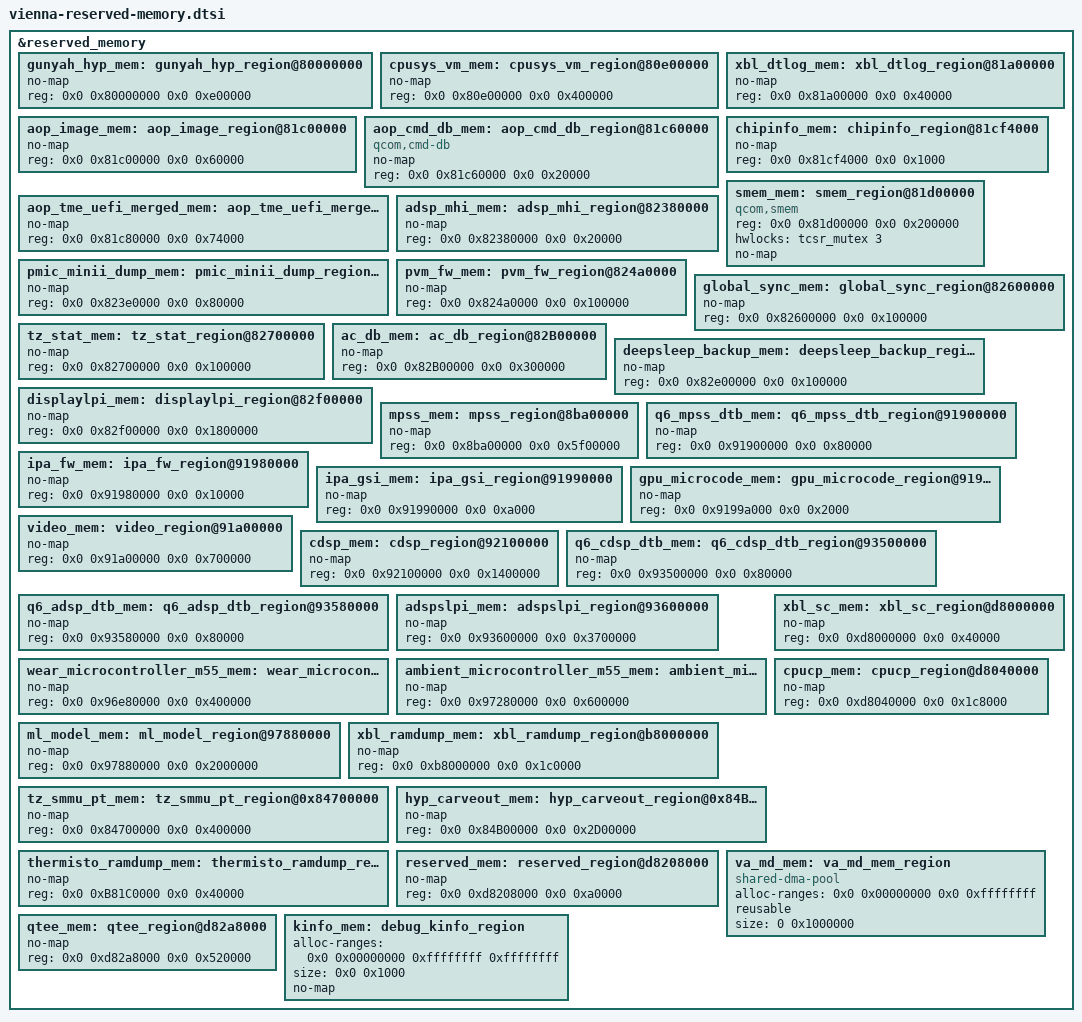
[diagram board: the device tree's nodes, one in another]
// SPDX-License-Identifier: BSD-3-Clause
/*
 * Copyright (c) Qualcomm Technologies, Inc. and/or its subsidiaries.
 */

&reserved_memory {
	#address-cells = <2>;
	#size-cells = <2>;
	ranges;

	gunyah_hyp_mem: gunyah_hyp_region@80000000 {
		no-map;
		reg = <0x0 0x80000000 0x0 0xe00000>;
	};

	cpusys_vm_mem: cpusys_vm_region@80e00000 {
		no-map;
		reg = <0x0 0x80e00000 0x0 0x400000>;
	};

	/*
	 * hyp_tags_mem is dynamically removed from the RAM
	 * partition tables before boot occurs. Size of region
	 * varies.
	 */

	xbl_dtlog_mem: xbl_dtlog_region@81a00000 {
		no-map;
		reg = <0x0 0x81a00000 0x0 0x40000>;
	};

	aop_image_mem: aop_image_region@81c00000 {
		no-map;
		reg = <0x0 0x81c00000 0x0 0x60000>;
	};

	aop_cmd_db_mem: aop_cmd_db_region@81c60000 {
		compatible = "qcom,cmd-db";
		no-map;
		reg = <0x0 0x81c60000 0x0 0x20000>;
	};

	/* merged aop_config, tme_crash_dump, tme_log and uefi_log regions */
	aop_tme_uefi_merged_mem: aop_tme_uefi_merged_region@81c80000 {
		no-map;
		reg = <0x0 0x81c80000 0x0 0x74000>;
	};

	chipinfo_mem: chipinfo_region@81cf4000 {
		no-map;
		reg = <0x0 0x81cf4000 0x0 0x1000>;
	};

	/* secdata region can be reused by apps */
	smem_mem: smem_region@81d00000 {
		compatible = "qcom,smem";
		reg = <0x0 0x81d00000 0x0 0x200000>;
		hwlocks = <&tcsr_mutex 3>;
		no-map;
	};

	adsp_mhi_mem: adsp_mhi_region@82380000 {
		no-map;
		reg = <0x0 0x82380000 0x0 0x20000>;
	};

	pmic_minii_dump_mem: pmic_minii_dump_region@823e0000 {
		no-map;
		reg = <0x0 0x823e0000 0x0 0x80000>;
	};

	pvm_fw_mem: pvm_fw_region@824a0000 {
		no-map;
		reg = <0x0 0x824a0000 0x0 0x100000>;
	};

	/* hyp_mem_database_mem is removed by HYP in the RAM partition table */
	global_sync_mem: global_sync_region@82600000 {
		no-map;
		reg = <0x0 0x82600000 0x0 0x100000>;
	};

	tz_stat_mem: tz_stat_region@82700000 {
		no-map;
		reg = <0x0 0x82700000 0x0 0x100000>;
	};

	ac_db_mem: ac_db_region@82B00000 {
		no-map;
		reg = <0x0 0x82B00000 0x0 0x300000>;
	};

	deepsleep_backup_mem: deepsleep_backup_region@82e00000 {
		no-map;
		reg = <0x0 0x82e00000 0x0 0x100000>;
	};

	displaylpi_mem: displaylpi_region@82f00000 {
		no-map;
		reg = <0x0 0x82f00000 0x0 0x1800000>;
	};

	mpss_mem: mpss_region@8ba00000 {
		no-map;
		reg = <0x0 0x8ba00000 0x0 0x5f00000>;
	};

	q6_mpss_dtb_mem: q6_mpss_dtb_region@91900000 {
		no-map;
		reg = <0x0 0x91900000 0x0 0x80000>;
	};

	ipa_fw_mem: ipa_fw_region@91980000 {
		no-map;
		reg = <0x0 0x91980000 0x0 0x10000>;
	};

	ipa_gsi_mem: ipa_gsi_region@91990000 {
		no-map;
		reg = <0x0 0x91990000 0x0 0xa000>;
	};

	gpu_microcode_mem: gpu_microcode_region@9199a000 {
		no-map;
		reg = <0x0 0x9199a000 0x0 0x2000>;
	};

	video_mem: video_region@91a00000 {
		no-map;
		reg = <0x0 0x91a00000 0x0 0x700000>;
	};

	cdsp_mem: cdsp_region@92100000 {
		no-map;
		reg = <0x0 0x92100000 0x0 0x1400000>;
	};

	q6_cdsp_dtb_mem: q6_cdsp_dtb_region@93500000 {
		no-map;
		reg = <0x0 0x93500000 0x0 0x80000>;
	};

	q6_adsp_dtb_mem: q6_adsp_dtb_region@93580000 {
		no-map;
		reg = <0x0 0x93580000 0x0 0x80000>;
	};

	adspslpi_mem: adspslpi_region@93600000 {
		no-map;
		reg = <0x0 0x93600000 0x0 0x3700000>;
	};

	wear_microcontroller_m55_mem: wear_microcontroller_m55_region@96e80000 {
		no-map;
		reg = <0x0 0x96e80000 0x0 0x400000>;
	};

	ambient_microcontroller_m55_mem: ambient_microcontroller_m55_region@97280000 {
		no-map;
		reg = <0x0 0x97280000 0x0 0x600000>;
	};

	ml_model_mem: ml_model_region@97880000 {
		no-map;
		reg = <0x0 0x97880000 0x0 0x2000000>;
	};

	/* UEFI region at 0xa7000000 is reclaimed by Linux */

	xbl_ramdump_mem: xbl_ramdump_region@b8000000 {
		no-map;
		reg = <0x0 0xb8000000 0x0 0x1c0000>;
	};

	tz_smmu_pt_mem: tz_smmu_pt_region@0x84700000 {
		no-map;
		reg = <0x0 0x84700000 0x0 0x400000>;
	};

	hyp_carveout_mem: hyp_carveout_region@0x84B00000 {
		no-map;
		reg = <0x0 0x84B00000 0x0 0x2D00000>;
	};

	thermisto_ramdump_mem: thermisto_ramdump_region@0xB81C0000 {
		no-map;
		reg = <0x0 0xB81C0000 0x0 0x40000>;
	};

	xbl_sc_mem: xbl_sc_region@d8000000 {
		no-map;
		reg = <0x0 0xd8000000 0x0 0x40000>;
	};

	cpucp_mem: cpucp_region@d8040000 {
		no-map;
		reg = <0x0 0xd8040000 0x0 0x1c8000>;
	};

	reserved_mem: reserved_region@d8208000 {
		no-map;
		reg = <0x0 0xd8208000 0x0 0xa0000>;
	};

	va_md_mem: va_md_mem_region {
		compatible = "shared-dma-pool";
		alloc-ranges = <0x0 0x00000000 0x0 0xffffffff>;
		reusable;
		size = <0 0x1000000>;
	};

	qtee_mem: qtee_region@d82a8000 {
		no-map;
		reg = <0x0 0xd82a8000 0x0 0x520000>;
	};

	kinfo_mem: debug_kinfo_region {
		alloc-ranges = <0x0 0x00000000 0xffffffff 0xffffffff>;
		size = <0x0 0x1000>;
		no-map;
	};

	/*
	 * ta/tags mem is dynamically removed from the RAM
	 * partition tables before boot occurs. Size of region
	 * varies.
	 */
};
